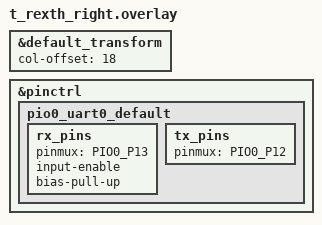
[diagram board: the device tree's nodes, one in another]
#include "t_rexth.dtsi"

&default_transform {
  col-offset = <18>;
};

&pinctrl {
  pio0_uart0_default: pio0_uart0_default {
    rx_pins {
      pinmux = <PIO0_P13>;
      input-enable;
      bias-pull-up;
    };
    tx_pins {
      pinmux = <PIO0_P12>;
    };
  };
};
